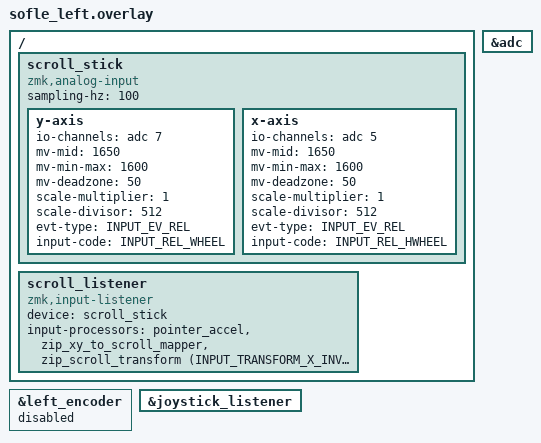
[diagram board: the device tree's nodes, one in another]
/* config/sofle_left.overlay */
#include "sofle.dtsi"
#include <dt-bindings/zmk/input_transform.h>
#include <dt-bindings/zmk/mouse.h>
#include <zephyr/dt-bindings/input/input-event-codes.h>

&adc {
    status = "okay";
};

&left_encoder {
    status = "disabled";
};

/ {
    scroll_stick: scroll_stick {
        compatible = "zmk,analog-input";
        status = "okay";
        sampling-hz = <100>;

        /* Vertical Scroll (Pin P0.31/AIN7) - LEFT SIDE */
        y-axis {
            io-channels = <&adc 7>;
            mv-mid = <1650>;
            mv-min-max = <1600>;
            mv-deadzone = <50>;
            scale-multiplier = <1>;
            scale-divisor = <512>;
            evt-type = <INPUT_EV_REL>;
            input-code = <INPUT_REL_WHEEL>;
        };

        /* Horizontal Scroll (Pin P0.29/AIN5) - LEFT SIDE */
        x-axis {
            io-channels = <&adc 5>;
            mv-mid = <1650>;
            mv-min-max = <1600>;
            mv-deadzone = <50>;
            scale-multiplier = <1>;
            scale-divisor = <512>;
            evt-type = <INPUT_EV_REL>;
            input-code = <INPUT_REL_HWHEEL>;
        };
    };

    scroll_listener {
        compatible = "zmk,input-listener";
        status = "okay";
        device = <&scroll_stick>;
        input-processors = <&pointer_accel>, <&zip_xy_to_scroll_mapper>, <&zip_scroll_transform (INPUT_TRANSFORM_X_INVERT | INPUT_TRANSFORM_Y_INVERT)>;
    };
};

&joystick_listener {
    status = "okay";
};
